# npcx9m6f register map
Registers are 8-bit, read-write, no defined reset value unless marked. A register's access mark holds for its fields unless they carry their own. Offsets are from the block's base; [hi:lo] are bit positions; {n}, {i} and the like mark numbered series.

## SHM — SHM Module
Base 0x40010000
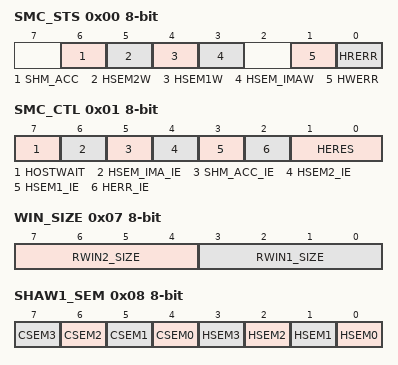
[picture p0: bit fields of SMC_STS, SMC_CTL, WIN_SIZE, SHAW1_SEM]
0x00 SMC_STS
  [6] SHM_ACC, [5] HSEM2W, [4] HSEM1W, [3] HSEM_IMAW, [1] HWERR, [0] HRERR
0x01 SMC_CTL
  [7] HOSTWAIT, [6] HSEM_IMA_IE, [5] SHM_ACC_IE, [4] HSEM2_IE, [3] HSEM1_IE, [2] HERR_IE, [1:0] HERES
0x02 SHM_CTL
  [6] STALL_HOST
0x05 IMA_WIN_SIZE
  [3:0] IMA_SIZE
0x07 WIN_SIZE
  [7:4] RWIN2_SIZE, [3:0] RWIN1_SIZE
0x08 SHAW1_SEM
  [n+4] CSEM{n} (n=0..3), [n] HSEM{n} (n=0..3)
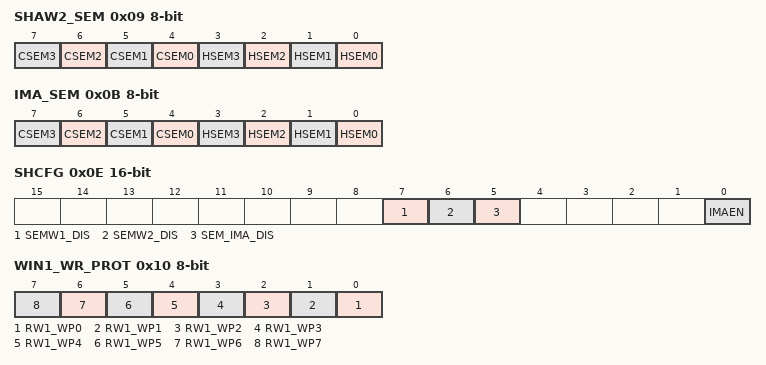
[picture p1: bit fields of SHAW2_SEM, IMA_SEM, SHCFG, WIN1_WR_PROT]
0x09 SHAW2_SEM
  [n+4] CSEM{n} (n=0..3), [n] HSEM{n} (n=0..3)
0x0B IMA_SEM
  [n+4] CSEM{n} (n=0..3), [n] HSEM{n} (n=0..3)
0x0E SHCFG 16-bit
  [7] SEMW1_DIS, [6] SEMW2_DIS, [5] SEM_IMA_DIS, [0] IMAEN
0x10 WIN1_WR_PROT
  [n] RW1_WP{n} (n=0..7)
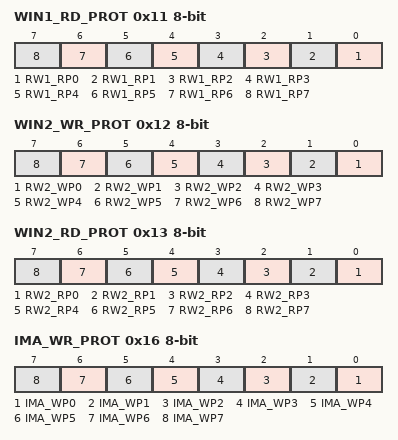
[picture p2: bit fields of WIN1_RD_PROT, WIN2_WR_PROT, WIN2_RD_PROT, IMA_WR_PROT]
0x11 WIN1_RD_PROT
  [n] RW1_RP{n} (n=0..7)
0x12 WIN2_WR_PROT
  [n] RW2_WP{n} (n=0..7)
0x13 WIN2_RD_PROT
  [n] RW2_RP{n} (n=0..7)
0x16 IMA_WR_PROT
  [n] IMA_WP{n} (n=0..7)
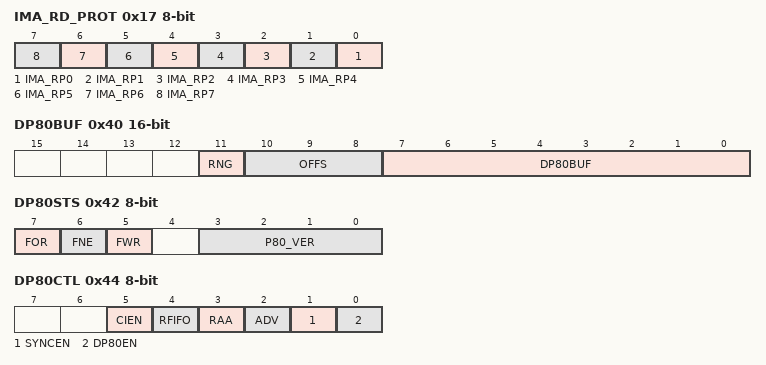
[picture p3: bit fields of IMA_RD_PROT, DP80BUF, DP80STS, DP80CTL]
0x17 IMA_RD_PROT
  [n] IMA_RP{n} (n=0..7)
0x20 WIN_BASE1 32-bit
0x24 WIN_BASE2 32-bit
0x2C IMA_BASE 32-bit
0x3A RST_CFG
  [7] LRESET_PLTRST_DIS
0x40 DP80BUF 16-bit
  [11] RNG, [10:8] OFFS, [7:0] DP80BUF
0x42 DP80STS
  [7] FOR, [6] FNE, [5] FWR, [3:0] P80_VER
0x44 DP80CTL
  [5] CIEN, [4] RFIFO, [3] RAA, [2] ADV, [1] SYNCEN, [0] DP80EN
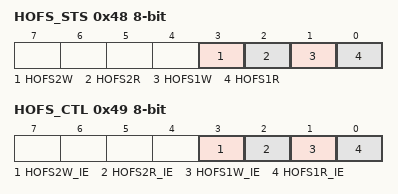
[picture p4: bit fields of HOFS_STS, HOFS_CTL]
0x48 HOFS_STS
  [3] HOFS2W, [2] HOFS2R, [1] HOFS1W, [0] HOFS1R
0x49 HOFS_CTL
  [3] HOFS2W_IE, [2] HOFS2R_IE, [1] HOFS1W_IE, [0] HOFS1R_IE
0x4A COFS2 16-bit
  [11:0] COFS2_DAT
0x4C COFS1 16-bit
  [11:0] COFS1_DAT
0x50 IHOFS2 16-bit
  [11:0] HOFS2_DAT
0x52 IHOFS1 16-bit
  [11:0] HOFS1_DAT
0x7F VERSION

## MSWC — MSWC Module
Base 0x400C1000
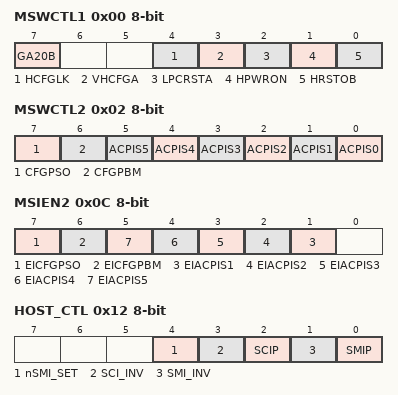
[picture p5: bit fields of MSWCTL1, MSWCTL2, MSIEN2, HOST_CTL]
0x00 MSWCTL1
  [7] GA20B, [4] HCFGLK, [3] VHCFGA, [2] LPCRSTA, [1] HPWRON, [0] HRSTOB
0x02 MSWCTL2
  [7] CFGPSO, [6] CFGPBM, [n] ACPIS{n} (n=0..5)
0x08 HCBAL
  [7:0] HCBA7-0
0x0A HCBAH
  [7:0] HCBA15-0
0x0C MSIEN2
  [7] EICFGPSO, [6] EICFGPBM, [n] EIACPIS{n} (n=1..5)
0x0E MSHES0
  [7] MODIRQ_STS
0x10 MSHEIE0
  [7] MODIRQ_EN
0x12 HOST_CTL
  [4] nSMI_SET, [3] SCI_INV, [2] SCIP, [1] SMI_INV, [0] SMIP
0x14 SMIP_LEN
0x16 SCIP_LEN
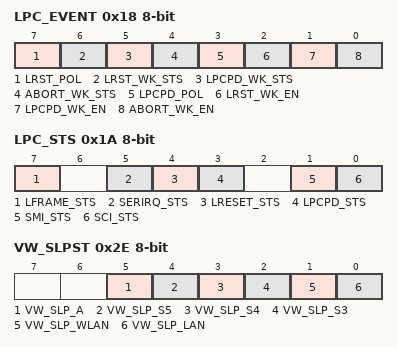
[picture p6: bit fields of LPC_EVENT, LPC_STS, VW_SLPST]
0x18 LPC_EVENT
  [7] LRST_POL, [6] LRST_WK_STS, [5] LPCPD_WK_STS, [4] ABORT_WK_STS, [3] LPCPD_POL, [2] LRST_WK_EN, [1] LPCPD_WK_EN, [0] ABORT_WK_EN
0x1A LPC_STS
  [7] LFRAME_STS, [5] SERIRQ_STS, [4] LRESET_STS, [3] LPCPD_STS, [1] SMI_STS, [0] SCI_STS
0x1C SRID_CR
  [7:0] CHIP_ID_CR
0x1E MSWC_VER
0x20 SID_CR
  [7:0] FAM_ID
0x22 DEVICE_ID_CR
  [4:0] DEV_ID_CR
0x2E VW_SLPST
  [5] VW_SLP_A, [4] VW_SLP_S5, [3] VW_SLP_S4, [2] VW_SLP_S3, [1] VW_SLP_WLAN, [0] VW_SLP_LAN

## MailBox — MailBox Module
Base 0x400A1000
0x00 HOST_TO_EC
0x01 EC_TO_HOST
{0x10+i} GPD_{i} (i=0..47)
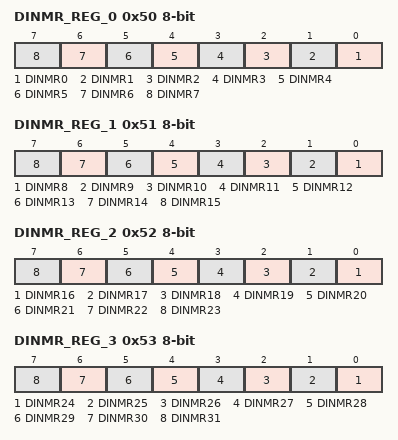
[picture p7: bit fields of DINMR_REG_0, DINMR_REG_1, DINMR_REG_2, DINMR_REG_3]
0x50 DINMR_REG_0
  [n] DINMR{n} (n=0..7)
0x51 DINMR_REG_1
  [n-8] DINMR{n} (n=8..15)
0x52 DINMR_REG_2
  [n-16] DINMR{n} (n=16..23)
0x53 DINMR_REG_3
  [n-24] DINMR{n} (n=24..31)
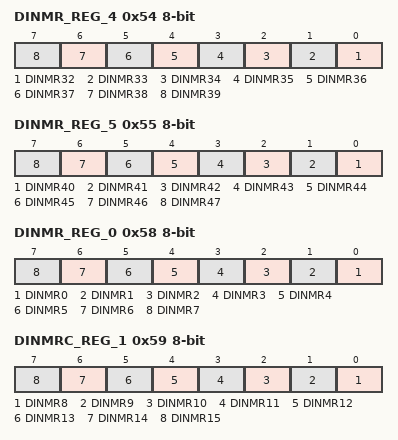
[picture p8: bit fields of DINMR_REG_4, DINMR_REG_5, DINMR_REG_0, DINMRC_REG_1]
0x54 DINMR_REG_4
  [n-32] DINMR{n} (n=32..39)
0x55 DINMR_REG_5
  [n-40] DINMR{n} (n=40..47)
0x58 DINMR_REG_0
  [n] DINMR{n} (n=0..7)
0x59 DINMRC_REG_1
  [n-8] DINMR{n} (n=8..15)
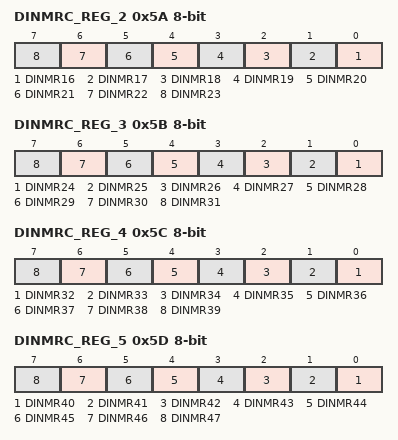
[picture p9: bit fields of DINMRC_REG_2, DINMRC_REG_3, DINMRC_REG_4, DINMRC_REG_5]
0x5A DINMRC_REG_2
  [n-16] DINMR{n} (n=16..23)
0x5B DINMRC_REG_3
  [n-24] DINMR{n} (n=24..31)
0x5C DINMRC_REG_4
  [n-32] DINMR{n} (n=32..39)
0x5D DINMRC_REG_5
  [n-40] DINMR{n} (n=40..47)
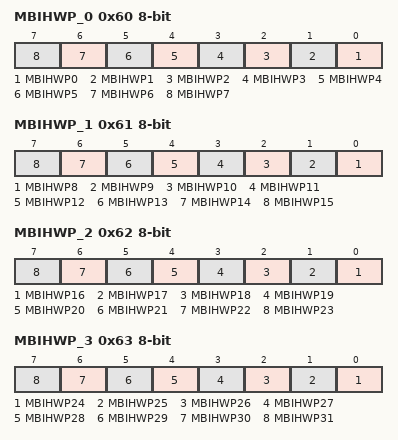
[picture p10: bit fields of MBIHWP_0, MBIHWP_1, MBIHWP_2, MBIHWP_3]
0x60 MBIHWP_0
  [n] MBIHWP{n} (n=0..7)
0x61 MBIHWP_1
  [n-8] MBIHWP{n} (n=8..15)
0x62 MBIHWP_2
  [n-16] MBIHWP{n} (n=16..23)
0x63 MBIHWP_3
  [n-24] MBIHWP{n} (n=24..31)
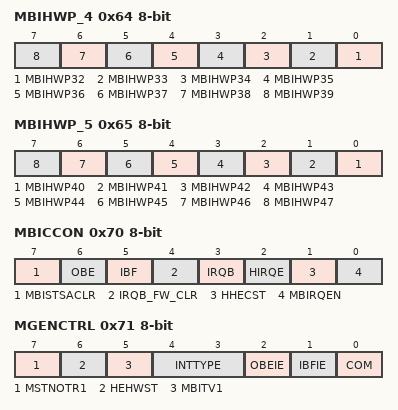
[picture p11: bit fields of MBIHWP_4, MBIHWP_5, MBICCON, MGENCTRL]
0x64 MBIHWP_4
  [n-32] MBIHWP{n} (n=32..39)
0x65 MBIHWP_5
  [n-40] MBIHWP{n} (n=40..47)
0x70 MBICCON
  [7] MBISTSACLR, [6] OBE, [5] IBF, [4] IRQB_FW_CLR, [3] IRQB, [2] HIRQE, [1] HHECST, [0] MBIRQEN
0x71 MGENCTRL
  [7] MSTNOTR1, [6] HEHWST, [5] MBITV1, [4:3] INTTYPE, [2] OBEIE, [1] IBFIE, [0] COM
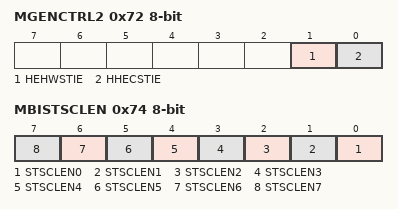
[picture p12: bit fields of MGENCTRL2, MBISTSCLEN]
0x72 MGENCTRL2
  [1] HEHWSTIE, [0] HHECSTIE
0x73 MBISTS
0x74 MBISTSCLEN
  [n] STSCLEN{n} (n=0..7)

## SCFG — SYSTEM CONFIGURATION
Base 0x400C3000
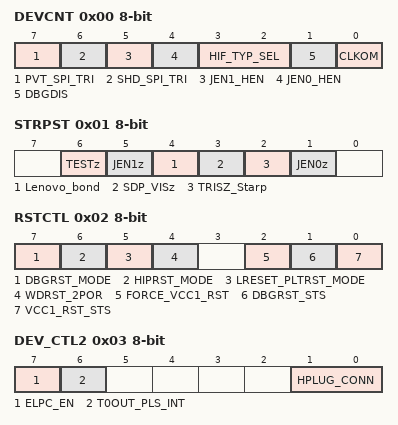
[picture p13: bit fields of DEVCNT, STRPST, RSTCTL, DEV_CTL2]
0x00 DEVCNT
  [7] PVT_SPI_TRI, [6] SHD_SPI_TRI, [5] JEN1_HEN, [4] JEN0_HEN, [3:2] HIF_TYP_SEL, [1] DBGDIS, [0] CLKOM
0x01 STRPST
  [6] TESTz, [5] JEN1z, [4] Lenovo_bond, [3] SDP_VISz, [2] TRISZ_Starp, [1] JEN0z
0x02 RSTCTL
  [7] DBGRST_MODE, [6] HIPRST_MODE, [5] LRESET_PLTRST_MODE, [4] WDRST_2POR, [2] FORCE_VCC1_RST, [1] DBGRST_STS, [0] VCC1_RST_STS
0x03 DEV_CTL2
  [7] ELPC_EN, [6] T0OUT_PLS_INT, [1:0] HPLUG_CONN
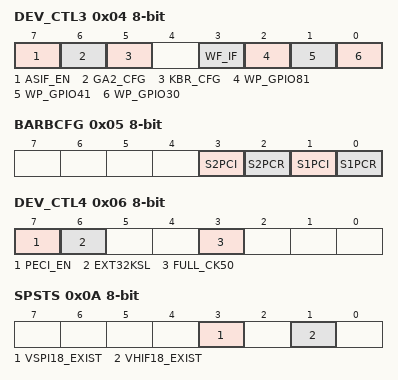
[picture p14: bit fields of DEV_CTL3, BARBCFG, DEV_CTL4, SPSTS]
0x04 DEV_CTL3
  [7] ASIF_EN, [6] GA2_CFG, [5] KBR_CFG, [3] WF_IF, [2] WP_GPIO81, [1] WP_GPIO41, [0] WP_GPIO30
0x05 BARBCFG
  [3] S2PCI, [2] S2PCR, [1] S1PCI, [0] S1PCR
0x06 DEV_CTL4
  [7] PECI_EN, [6] EXT32KSL, [3] FULL_CK50
0x0A SPSTS
  [3] VSPI18_EXIST, [1] VHIF18_EXIST
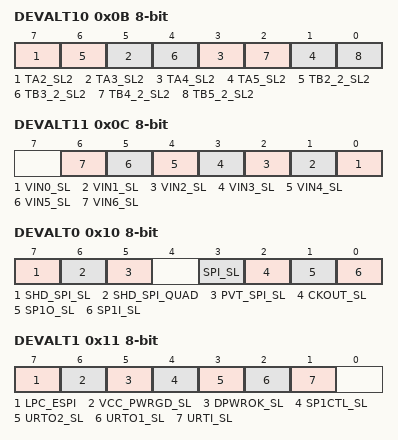
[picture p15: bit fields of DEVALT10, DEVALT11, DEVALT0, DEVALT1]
0x0B DEVALT10
  [11-2n] TA{n}_SL2 (n=2..5), [10-2n] TB{n}_2_SL2 (n=2..5)
0x0C DEVALT11
  [n] VIN{n}_SL (n=0..6)
0x10 DEVALT0
  [7] SHD_SPI_SL, [6] SHD_SPI_QUAD, [5] PVT_SPI_SL, [3] SPI_SL, [2] CKOUT_SL, [1] SP1O_SL, [0] SP1I_SL
0x11 DEVALT1
  [7] LPC_ESPI, [6] VCC_PWRGD_SL, [5] DPWROK_SL, [4] SP1CTL_SL, [3] URTO2_SL, [2] URTO1_SL, [1] URTI_SL
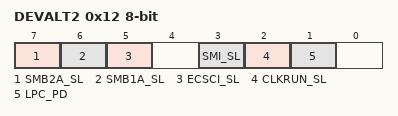
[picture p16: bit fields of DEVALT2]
0x12 DEVALT2
  [7] SMB2A_SL, [6] SMB1A_SL, [5] ECSCI_SL, [3] SMI_SL, [2] CLKRUN_SL, [1] LPC_PD
0x13 DEVALT3
  [7] TA1_2_SL, [6] TB1_2_SL, [5] TB3_1_SL, [4] TA3_1_SL, [3] TB2_1_SL, [2] TB1_1_SL, [1] TA2_1_SL, [0] TA1_1_SL
0x14 DEVALT4
  [6] PS2_2_SL, [5] PS2_1_SL, [4] PS2_3_SL, [n] DAC{n}_SL (n=0..3)
0x15 DEVALT5
  [7] H_PWM_SL, [6] G_PWM_SL, [5] F_PWM_SL, [4] E_PWM_SL, [3] D_PWM_SL, [2] C_PWM_SL, [1] B_PWM_SL, [0] A_PWM_SL
0x16 DEVALT6
  [n] ADC{n}_SL (n=0..7)
0x17 DEVALT7
  [n-10] KSO{n}_SL (n=12..17)
0x18 DEVALT8
  [7] I_PWM_SL, [6] J_PWM_SL, [5] K_PWM_SL, [4] L_PWM_SL, [3] M_PWM_SL, [2] KBRST_SL, [1] GA20_SL
0x19 DEVALT9
  [7] GPC23_SL, [6] GPC01_SL, [5] GPB47_SL, [4] GPB03_SL, [3] GPA67_SL, [2] GPA45_SL, [1] GPF07_SL, [0] GPA03_SL
0x1A DEVALTA
  [7] SMB4A_SL, [6] SMB3A_SL, [2] SMB5A_SL, [1] SMB5B_SL
0x1B DEVALTB
  [4] RTS1_SL, [3] CTS1_SL, [2] RI1_SL
0x1C DEVALTC
  [8-n] SMB{n}B_SL (n=1..4), [3] ADC11, [2] ADC10, [1] ADC9_SL, [0] ADC8_SL
0x1D DEVALTD
  [5] PSL_IN2_SL, [4] PSL_IN2_AHI, [3] PSL_IN1_SL, [2] PSL_IN1_AHI
0x1E DEVALTE
  [5] SPI2_SL, [4] 1WIRE_SL, [3] VDO2_Sl, [2] VDI2_SL, [1] VDO1_SL, [0] VDI1_SL
0x1F DEVALTF
  [7] VCI_OUT_SL, [n+1] VCI_IN{n}_SL (n=0..5), [0] VCI_OVRD_SL
0x20 LFCGCALL
  [7:0] LCFG_CAL_LOW
0x21 LFCGCALLCNT
  [7] CALVV, [1] LCREG_CTL_EN, [0] LCFG_CAL_HIGH
0x24 DEVALTCX
  [n+1] VCI_IN{n}_AHI (n=0..5)
0x25 DEVALTDX
  [5] PSL_IN4_SL, [4] PSL_IN4_AHI, [3] PSL_IN3_SL, [2] PSL_IN3_AHI, [1] VCI_FW_BIT, [0] VCI_OUT_GPO
0x28 PUPD_EN0
  [2n-1] SMB{n}B_PUE (n=1..4), [2n-2] SMB{n}A_PUE (n=1..4)
0x29 PUPD_EN1
  [7] SHDF_SPI_PUD, [6] PVT_SPI_PUD, [0] SMB5A_PUE
0x2A LV_GPIO_CTL0
  [7] GPIO94_LV, [6] GPIO86_LV, [5] GPIO85_LV, [4] GPIO80_LV, [3] GPIO54_LV, [2] GPIO40_LV, [1] GPIO21_LV, [0] GPIO20_LV
0x2B LV_GPIO_CTL1
  [7] GPIOE2_LV, [6] GPIOE1_LV, [5] GPIO52_LV, [4] GPIO50_LV, [3] GPIO44_LV, [2] GPIO46_LV, [1] GPIOD6_LV, [0] GPIOD5_LV
0x2C LV_GPIO_CTL2
  [7] GPIOE4_LV, [6] GPIOE3_LV, [5] GPIO51_LV, [4] GPIO45_LV, [3] GPIO15_LV, [2] GPIO13_LV, [1] GPIO03_LV, [0] GPIO01_LV
0x2D LV_GPIO_CTL3
  [7] GPIO47_LV, [6] GPIO53_LV, [5] GPIO23_LV, [4] GPIO31_LV, [3] GPIO73_LV, [2] GPIO74_LV, [1] GPIO17_LV, [0] GPIO22_LV
0x2F SCFG_VER
